# GAP8 register map
Vendor: GreenWaves Technologies SAS; Series: GAP8; File version: 1.3.1
CPU: other r1p0, little endian, MPU, no FPU, I-cache, DTCM, false interrupt priority bits
Registers are 32-bit, read-write, reset 0x0 unless marked. A register's access mark holds for its fields unless they carry their own. Offsets are from the block's base; [hi:lo] are bit positions; {n}, {i} and the like mark numbered series.

## udma_ctrl — uDMA control unit
Base 0x1A102780
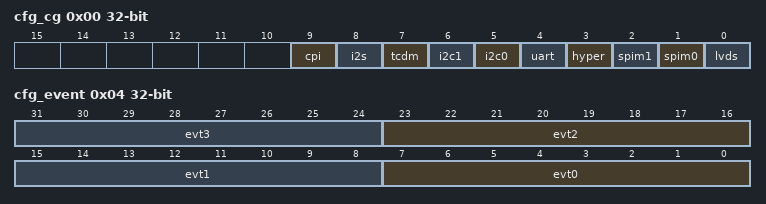
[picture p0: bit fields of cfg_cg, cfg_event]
0x00 cfg_cg — uDMA interfaces clock gate configuration register.
  [9] cpi — uDMA interfaces clock gate configuration for CPI
    0=CPI interface clock gate is enabled; 1=CPI interface clock gate is disabled
  [8] i2s — uDMA interfaces clock gate configuration for I2S
    0=I2S interface clock gate is enabled; 1=I2S interface clock gate is disabled
  [7] tcdm — uDMA interfaces clock gate configuration for TCDM
    0=TCDM interface clock gate is enabled; 1=TCDM interface clock gate is disabled
  [6] i2c1 — uDMA interfaces clock gate configuration for I2C1
    0=I2C1 interface clock gate is enabled; 1=I2C1 interface clock gate is disabled
  [5] i2c0 — uDMA interfaces clock gate configuration for I2C0
    0=I2C0 interface clock gate is enabled; 1=I2C0 interface clock gate is disabled
  [4] uart — uDMA interfaces clock gate configuration for UART
    0=UART interface clock gate is enabled; 1=UART interface clock gate is disabled
  [3] hyper — uDMA interfaces clock gate configuration for HYPER
    0=HYPER interface clock gate is enabled; 1=HYPER interface clock gate is disabled
  [2] spim1 — uDMA interfaces clock gate configuration for SPIM1
    0=SPIM1 interface clock gate is enabled; 1=SPIM1 interface clock gate is disabled
  [1] spim0 — uDMA interfaces clock gate configuration for SPIM0
    0=SPIM0 interface clock gate is enabled; 1=SPIM0 interface clock gate is disabled
  [0] lvds — uDMA interfaces clock gate configuration for LVDS
    0=LVDS interface clock gate is enabled; 1=LVDS interface clock gate is disabled
0x04 cfg_event — uDMA interfaces trigger events configuration register.
  [8n+7:8n] evt{n} (n=0..3) — uDMA interfaces trigger event {n} configuration bitfield. CFG_EVT{n} selects which SoC event is propageted to uDMA interface trigger event {n}.

## fc_ctrl — FC control unit
Base 0x1B200000
0x00 eoc ro — End of computation status register.
  [0] eoc — End of computation status bitfield
    on read: 0=computation still on-going on SoC domain and/or Cluster domain; 1=no more computation on SoC domain nor Cluster domain
0x40 boot_addr reset 0x1A000000 — Boot address configuration register.
  [31:0] ba — Boot address configuration bitfield. The FC_CORE will fetch first instruction at (BA+RESET_EXCEPTION_OFFSET).

## fc_event_unit
Base 0x1B200800
0x00 evt_mask — Input event mask configuration register.
  [31:0] em — Input event mask configuration bitfield: - EM[i]=1'b0: Input event request i is masked - EM[i]=1'b1: Input event request i is not masked
0x04 evt_mask_and wo — Input event mask update command register with bitwise AND operation.
  [31:0] ema — Input event mask configuration bitfield update with bitwise AND operation. It allows clearing EM[i] if EMA[i]=1'b1.
0x08 evt_mask_or wo — Input event mask update command register with bitwise OR operation.
  [31:0] emo — Input event mask configuration bitfield update with bitwise OR operation. It allows setting EM[i] if EMO[i]=1'b1.
0x0C irq_mask — Interrupt request mask configuration register.
  [31:0] im — Interrupt request mask configuration bitfield: - bit[i]=1'b0: Interrupt request i is masked - bit[i]=1'b1: Interrupt request i is not masked
0x10 irq_mask_and wo — Interrupt request mask update command register with bitwise AND operation.
  [31:0] ima — Interrupt request mask configuration bitfield update with bitwise AND operation. It allows clearing IM[i] if IMA[i]=1'b1.
0x14 irq_mask_or wo — Interrupt request mask update command register with bitwise OR operation.
  [31:0] imo — Interrupt request mask configuration bitfield update with bitwise OR operation. It allows setting IM[i] if IMO[i]=1'b1.
0x18 clock_status ro — FC_CORE clock status register.
  [0] cs — FC_CORE clock status bitfield: - CS=1'b0: FC_CORE clocked is gated - CS=1'b1: FC_CORE clocked is running
0x1C event_buffer ro — Pending input events status register.
  [31:0] eb — Pending input events status bitfield. EB[i]=1'b1 means that one or more input event i request are pending.
0x20 event_buffer_masked ro — Pending input events status register with EVT_MASK applied.
  [31:0] ebm — Pending input events status bitfield with EM applied. EBM[i]=1'b1 means that one or more input event i request are pending.
0x24 event_buffer_irq_masked ro — Pending input events status register with IRQ_MASK applied.
  [31:0] ibm — Pending input events status bitfield with IM applied. IBM[i]=1'b1 means that one or more input events i are pending.
0x28 event_buffer_clear wo — Pending input events status clear command register.
  [31:0] ebc — Pending input events status clear command bitfield. It allows clearing EB[i] if EBC[i]=1'b1.
0x40 sec_irq_mask — FC_CORE secured mode interrupt request mask configuration register.
  [31:0] sim — Interrupt request mask configuration bitfield when FC_CORE is in secured mode: - bit[i]=1'b0: Interrupt request I is masked - bit[i]=1'b1: Interrupt request I is not masked
{0x600+4i} remote_sw_event_{i}_trig wo (i=0..7) — Remote software event {i} trigger command register.
  [31:0] trig — Writing any value will trigger SoC software event {i}
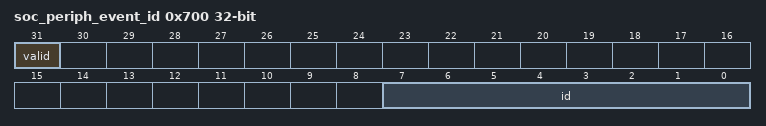
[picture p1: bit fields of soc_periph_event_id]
0x700 soc_periph_event_id ro — SoC peripheral event ID status register.
  [31] valid — Validity bit of SOC_PERIPH_EVENT_ID.ID bitfield.
  [7:0] id — Oldest SoC peripheral event ID status bitfield.

## fc_icache_ctrl — FC instruction cache control unit
Base 0x1B201400
0x00 enable wo — FC instruction cache unit enable configuration register.
  [0] en — FC instruction cache enable configuration bitfield
    on write: 0=disabled (feature is disabled); 1=enabled (feature is enabled)
0x04 flush wo — FC instruction cache unit flush command register.
  [0] fl — FC instruction cache fully flush command.
0x08 sel_flush wo — FC instruction cache unit selective flush command register.
  [31:0] addr — FC instruction cache selective flush address configuration bitfield.
0x0C status ro — FC instruction cache unit status register.
  [0] status — FC instruction cache pending action status flag
    on read: 0=no pending caching action; 1=pending caching action
